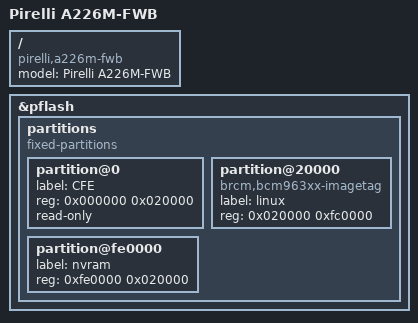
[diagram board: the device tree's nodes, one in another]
#include "bcm6358-pirelli-a226.dtsi"

/ {
	model = "Pirelli A226M-FWB";
	compatible = "pirelli,a226m-fwb", "brcm,bcm6358";
};

&pflash {
	status = "okay";

	partitions {
		compatible = "fixed-partitions";
		#address-cells = <1>;
		#size-cells = <1>;

		partition@0 {
			label = "CFE";
			reg = <0x000000 0x020000>;
			read-only;
		};

		partition@20000 {
			label = "linux";
			reg = <0x020000 0xfc0000>;
			compatible = "brcm,bcm963xx-imagetag";
		};

		partition@fe0000 {
			label = "nvram";
			reg = <0xfe0000 0x020000>;
		};
	};
};
